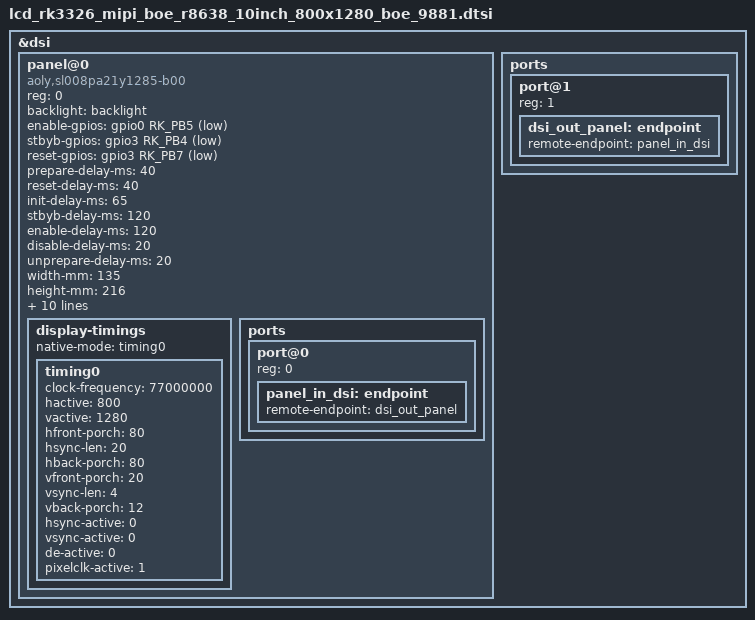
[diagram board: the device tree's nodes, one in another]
/*
* incar mipi lcd
*/
&dsi {
	status = "okay";

	panel@0 {
		compatible = "aoly,sl008pa21y1285-b00", "simple-panel-dsi";
		reg = <0>;
		backlight = <&backlight>;
		enable-gpios = <&gpio0 RK_PB5 GPIO_ACTIVE_LOW>;
		stbyb-gpios = <&gpio3 RK_PB4 GPIO_ACTIVE_LOW>;
		
		reset-gpios = <&gpio3 RK_PB7 GPIO_ACTIVE_LOW>;
		prepare-delay-ms = <40>;
		reset-delay-ms = <40>;
		init-delay-ms = <65>;
		stbyb-delay-ms = <120>;
		enable-delay-ms = <120>;
		disable-delay-ms = <20>;
		unprepare-delay-ms = <20>;

		width-mm = <135>;
		height-mm = <216>;

		dsi,flags = <(MIPI_DSI_MODE_VIDEO | MIPI_DSI_MODE_VIDEO_BURST |
			      MIPI_DSI_MODE_LPM | MIPI_DSI_MODE_EOT_PACKET)>;
		dsi,format = <MIPI_DSI_FMT_RGB888>;
		dsi,lanes = <4>;

		panel-init-sequence = [
39 00 04 FF 98 81 03 
//GIP_1

15 00 02 01 00 
15 00 02 02 00 
15 00 02 03 54        //STVA=STV0
15 00 02 04 D4        //STVB=STV1_2
15 00 02 05 00        //STVC
15 00 02 06 11        //STVA_Rise
15 00 02 07 09        //STVB_Rise
15 00 02 08 00        //STVC_Rise
15 00 02 09 00        //FTI1R(A)
15 00 02 0a 00        //FTI2R(B)
15 00 02 0b 00        //FTI3R(C)
15 00 02 0c 00        //FTI1F(A)
15 00 02 0d 00        //FTI2F(B)
15 00 02 0e 00        //FTI2F(C)
15 00 02 0f 26        //Duty=45%  //CLW1(ALR) 
15 00 02 10 26        //Duty=45%  //CLW2(ARR)
15 00 02 11 00           
15 00 02 12 00        
15 00 02 13 00        //CLWX(ATF)
15 00 02 14 00
15 00 02 15 00        //GPMRi(ALR)
15 00 02 16 00        //GPMRii(ARR)
15 00 02 17 00        //GPMFi(ALF)
15 00 02 18 00        //GPMFii(AFF)
15 00 02 19 00
15 00 02 1a 00
15 00 02 1b 00   
15 00 02 1c 00
15 00 02 1d 00
15 00 02 1e 40        //CLKA 40自動反 C0手動反(X8參考CLKB)
15 00 02 1f 80        //C0
15 00 02 20 06        //CLKA_Rise
15 00 02 21 01        //CLKA_Fall
15 00 02 22 00        //CLKB_Rise(keep toggle需設CLK A後一格)
15 00 02 23 00        //CLKB_Fall
15 00 02 24 00        //CLK keep toggle(AL) 8X往左看
15 00 02 25 00        //CLK keep toggle(AR) 8X往左看
15 00 02 26 00
15 00 02 27 00
15 00 02 28 33       //CLK Phase
15 00 02 29 33       //CLK overlap
15 00 02 2a 00  
15 00 02 2b 00
15 00 02 2c 00       //GCH R
15 00 02 2d 00       //GCL R 
15 00 02 2e 00       //GCH F        
15 00 02 2f 00       //GCL F
15 00 02 30 00
15 00 02 31 00
15 00 02 32 00       //GCH/L ext2/1行為  5E 01:31   5E 00:42
15 00 02 33 00
15 00 02 34 03       //VDD1&2 non-overlap 03:0us  04:2.62us
15 00 02 35 00       //GCH/    
15 00 02 36 00
15 00 02 37 00       //GCH/L
15 00 02 38 96	//VDD1&2 toggle  96:2.5sec   78:2sec
15 00 02 39 00
15 00 02 3a 00 
15 00 02 3b 00
15 00 02 3c 00
15 00 02 3d 00
15 00 02 3e 00
15 00 02 3f 00
15 00 02 40 00
15 00 02 41 00
15 00 02 42 00
15 00 02 43 00       //GCH/L
15 00 02 44 00


//GIP_2
15 00 02 50 00
15 00 02 51 23
15 00 02 52 45
15 00 02 53 67
15 00 02 54 89
15 00 02 55 ab
15 00 02 56 01
15 00 02 57 23
15 00 02 58 45
15 00 02 59 67
15 00 02 5a 89
15 00 02 5b ab
15 00 02 5c cd
15 00 02 5d ef

//GIP_3
15 00 02 5e 00
15 00 02 5f 0D     //FW_CGOUT_L[1]    CLK8
15 00 02 60 0D     //FW_CGOUT_L[2]    CLK8
15 00 02 61 0C     //FW_CGOUT_L[3]    CLK6
15 00 02 62 0C     //FW_CGOUT_L[4]    CLK6
15 00 02 63 0F     //FW_CGOUT_L[5]    CLK4
15 00 02 64 0F     //FW_CGOUT_L[6]    CLK4
15 00 02 65 0E     //FW_CGOUT_L[7]    CLK2
15 00 02 66 0E     //FW_CGOUT_L[8]    CLK2
15 00 02 67 08     //FW_CGOUT_L[9]    STV2
15 00 02 68 02     //FW_CGOUT_L[10]   
15 00 02 69 02     //FW_CGOUT_L[11]     
15 00 02 6a 02     //FW_CGOUT_L[12]  
15 00 02 6b 02     //FW_CGOUT_L[13]   
15 00 02 6c 02     //FW_CGOUT_L[14]      
15 00 02 6d 02     //FW_CGOUT_L[15]   
15 00 02 6e 02     //FW_CGOUT_L[16]   VGL    
15 00 02 6f 02     //FW_CGOUT_L[17]   VGL
15 00 02 70 14     //FW_CGOUT_L[18]   VDDO
15 00 02 71 15     //FW_CGOUT_L[19]   VDDE
15 00 02 72 06     //FW_CGOUT_L[20]   STV0
15 00 02 73 02     //FW_CGOUT_L[21]   
15 00 02 74 02     //FW_CGOUT_L[22]   
  
15 00 02 75 0D     //BW_CGOUT_L[1]   
15 00 02 76 0D     //BW_CGOUT_L[2]    
15 00 02 77 0C     //BW_CGOUT_L[3]    
15 00 02 78 0C     //BW_CGOUT_L[4]    
15 00 02 79 0F     //BW_CGOUT_L[5]     
15 00 02 7a 0F     //BW_CGOUT_L[6]     
15 00 02 7b 0E     //BW_CGOUT_L[7]   
15 00 02 7c 0E     //BW_CGOUT_L[8]    
15 00 02 7d 08     //BW_CGOUT_L[9]      
15 00 02 7e 02     //BW_CGOUT_L[10]
15 00 02 7f 02     //BW_CGOUT_L[11]    
15 00 02 80 02     //BW_CGOUT_L[12]   
15 00 02 81 02     //BW_CGOUT_L[13] 
15 00 02 82 02     //BW_CGOUT_L[14]      
15 00 02 83 02     //BW_CGOUT_L[15]   
15 00 02 84 02     //BW_CGOUT_L[16]      
15 00 02 85 02     //BW_CGOUT_L[17]
15 00 02 86 14     //BW_CGOUT_L[18]
15 00 02 87 15     //BW_CGOUT_L[19]
15 00 02 88 06     //BW_CGOUT_L[20]   
15 00 02 89 02     //BW_CGOUT_L[21]   
15 00 02 8A 02     //BW_CGOUT_L[22]   



//CMD_Page 4
39 00 04 FF 98 81 04

15 00 02 6E 3B           //VGH 18V
15 00 02 6F 57           //reg vcl + pumping ratio VGH=4x VGL=-3x
15 00 02 3A 24           //POWER SAVING
15 00 02 8D 1F           //VGL -12V
15 00 02 87 BA           //ESD
15 00 02 B2 D1
15 00 02 88 0B
15 00 02 38 01      
15 00 02 39 00
15 00 02 B5 07           //gamma bias
15 00 02 31 75
15 00 02 3B 98  			
			
//CMD_Page 1
39 00 04 FF 98 81 01
15 00 02 22 0A          //BGR  SS
15 00 02 31 09          ///Column inversion
15 00 02 35 07          //
15 00 02 53 7B          //VCOM1
15 00 02 55 40          //VCOM2 
15 00 02 50 86          // 4.3V  //95-> 4.5V //VREG1OUT
15 00 02 51 82          //-4.3V  //90->-4.5V //VREG2OUT
15 00 02 60 27          //SDT=2.8 
15 00 02 62 20

//============Gamma START=============

15 00 02 A0 00
15 00 02 A1 12
15 00 02 A2 20
15 00 02 A3 13
15 00 02 A4 14
15 00 02 A5 27
15 00 02 A6 1D
15 00 02 A7 1F
15 00 02 A8 7C
15 00 02 A9 1D
15 00 02 AA 2A
15 00 02 AB 6B
15 00 02 AC 1A
15 00 02 AD 18
15 00 02 AE 4E
15 00 02 AF 24
15 00 02 B0 2A
15 00 02 B1 4D
15 00 02 B2 5B
15 00 02 B3 23



//Neg 15 00 02
15 00 02 C0 00
15 00 02 C1 13
15 00 02 C2 20
15 00 02 C3 12
15 00 02 C4 15
15 00 02 C5 28
15 00 02 C6 1C
15 00 02 C7 1E
15 00 02 C8 7B
15 00 02 C9 1E
15 00 02 CA 29
15 00 02 CB 6C
15 00 02 CC 1A
15 00 02 CD 19
15 00 02 CE 4D
15 00 02 CF 22
15 00 02 D0 2A
15 00 02 D1 4D
15 00 02 D2 5B
15 00 02 D3 23


//============ Gamma END===========			
			

//CMD_Page 0			
39 00 04 FF 98 81 00
15 00 02 35 00  
05 78 01 11
05 64 01 29 	 

		];

		panel-init-sequence1 = [
39 00 03 E0 AB BA 
39 00 03 E1 BA AB 
39 00 05 B1 10 01 47 FF 
39 00 07 B2 0C 14 04 50 50 14 
39 00 04 B3 56 53 00 
39 00 04 B4 33 30 04 
39 00 08 B6 B0 00 00 10 00 10 00 
39 00 09 B7 0E 00 FF 08 08 FF FF 00 
39 00 08 B8 06 12 29 49 48 00 00 
39 00 27 B9 7C 4D 3B 2E 2C 1E 24 10 2C 2D 30 51 41 4A 3E 3B 31 1D 06 7C 4D 3B 2E 2C 1E 24 10 2C 2D 30 51 41 4A 3E 3B 31 1D 06 
39 00 11 C0 76 98 F2 34 55 44 54 44 80 04 7A 04 07 00 00 00 
39 00 0B C1 54 94 02 86 80 04 7A 04 54 00 
39 00 0D C2 37 09 08 89 08 11 22 33 44 82 18 00 
39 00 17 C3 8F 4F 0D 0D 13 13 11 11 05 02 02 02 02 02 02 24 24 1C 1D 08 02 02 
39 00 17 C4 0E 0E 0C 0C 12 12 10 10 04 02 02 02 02 02 02 24 24 1C 1D 08 02 02 
39 00 04 C5 E8 85 76 
39 00 03 C6 4D 4D 
39 00 07 C8 22 00 31 42 34 16 
39 00 03 CA CB 43 
39 00 09 CD 0E 64 64 2F 1E 6B 06 B3 
39 00 05 D2 E3 2B 38 00 
39 00 0C D4 00 01 00 0E 04 44 08 10 00 00 00 
39 00 09 E6 80 01 FF FF FF FF FF FF 
39 00 06 F0 12 03 20 00 FF 
15 00 02 F3 00
05 78 01 11
05 64 01 29 	 

		];

		panel-exit-sequence = [
			05 14 01 28
			05 78 01 10
		];

				
		display-timings {
			native-mode = <&timing0>;

			timing0: timing0 {
				clock-frequency = <77000000>;
				hactive = <800>;
				vactive = <1280>;
				hfront-porch = <80>;
				hsync-len = <20>;
				hback-porch = <80>;
				vfront-porch = <20>;
				vsync-len = <4>;
				vback-porch = <12>;
				hsync-active = <0>;
				vsync-active = <0>;
				de-active = <0>;
				pixelclk-active = <1>;
			};
		};
		ports {
			#address-cells = <1>;
			#size-cells = <0>;

			port@0 {
				reg = <0>;
				panel_in_dsi: endpoint {
					remote-endpoint = <&dsi_out_panel>;
				};
			};
		};
	};

	ports {
		#address-cells = <1>;
		#size-cells = <0>;

		port@1 {
			reg = <1>;
			dsi_out_panel: endpoint {
				remote-endpoint = <&panel_in_dsi>;
			};
		};
	};
};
